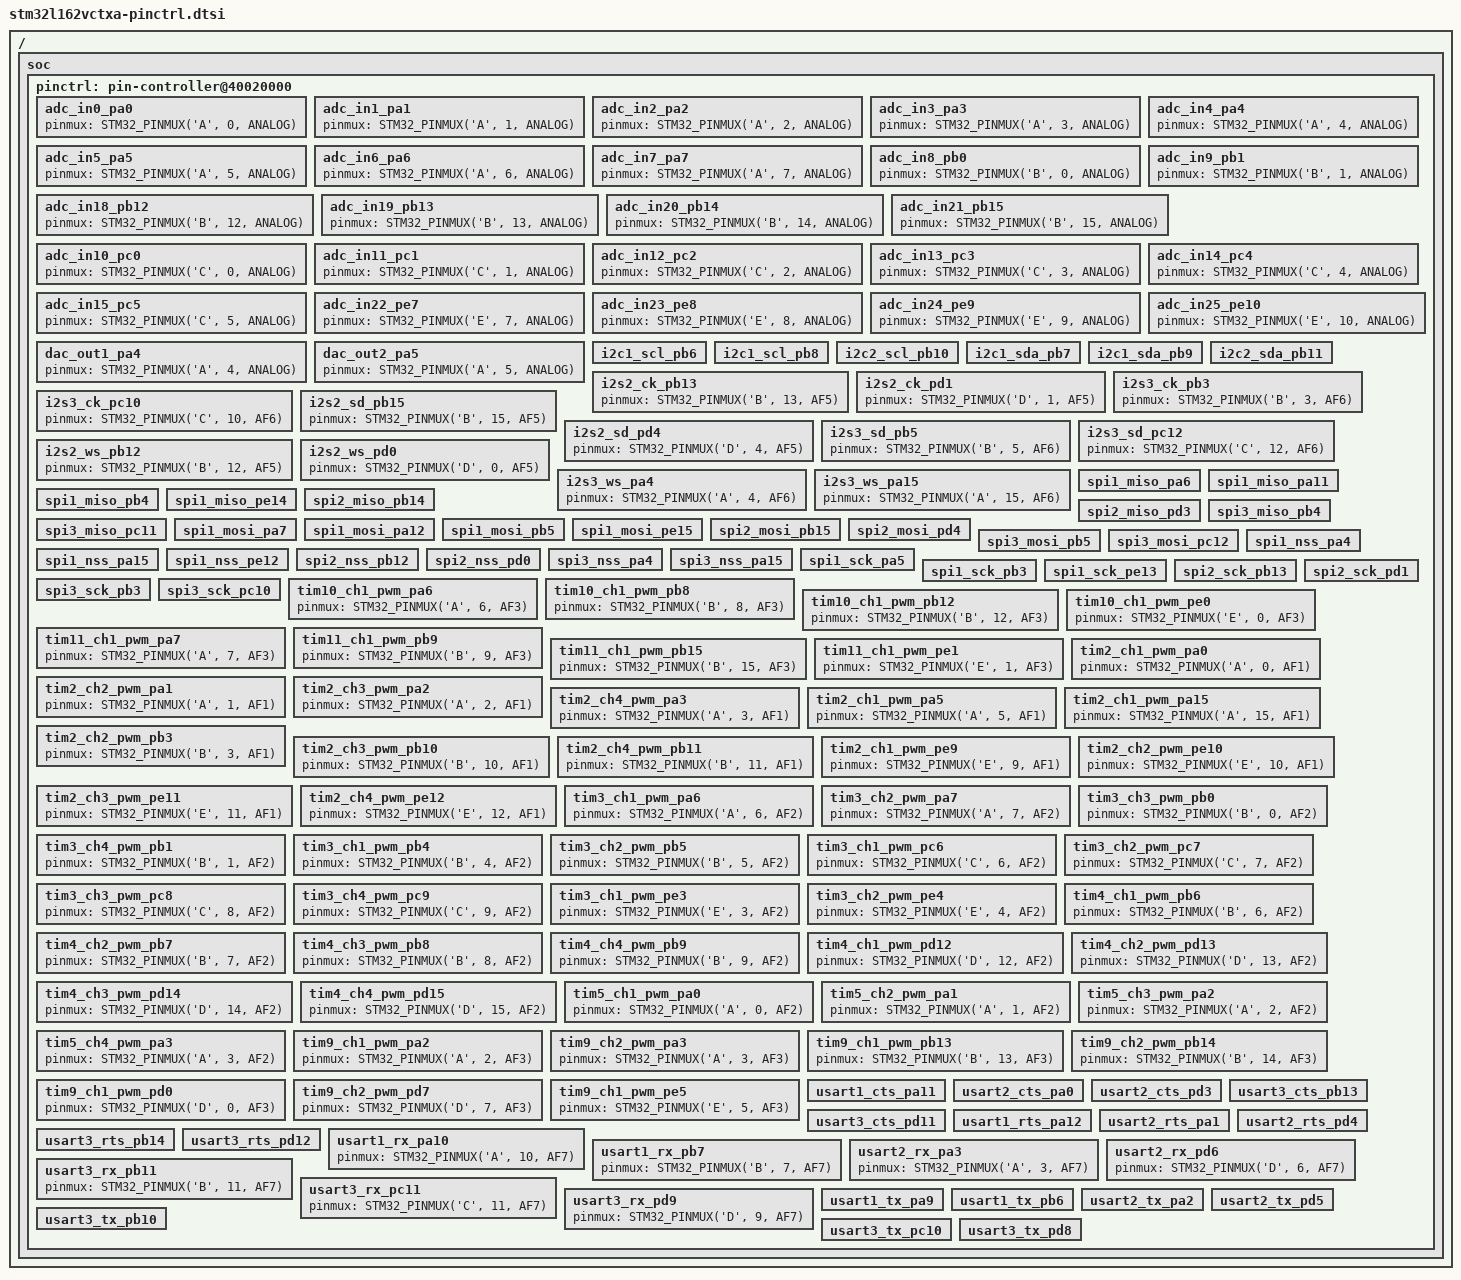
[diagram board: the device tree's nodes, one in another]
/*
 * NOTE: Autogenerated file using genpinctrl.py
 *
 * SPDX-License-Identifier: Apache-2.0
 */

#include <dt-bindings/pinctrl/stm32-pinctrl.h>

/ {
	soc {
		pinctrl: pin-controller@40020000 {

			/* ADC_IN / ADC_INN / ADC_INP */

			adc_in0_pa0: adc_in0_pa0 {
				pinmux = <STM32_PINMUX('A', 0, ANALOG)>;
			};

			adc_in1_pa1: adc_in1_pa1 {
				pinmux = <STM32_PINMUX('A', 1, ANALOG)>;
			};

			adc_in2_pa2: adc_in2_pa2 {
				pinmux = <STM32_PINMUX('A', 2, ANALOG)>;
			};

			adc_in3_pa3: adc_in3_pa3 {
				pinmux = <STM32_PINMUX('A', 3, ANALOG)>;
			};

			adc_in4_pa4: adc_in4_pa4 {
				pinmux = <STM32_PINMUX('A', 4, ANALOG)>;
			};

			adc_in5_pa5: adc_in5_pa5 {
				pinmux = <STM32_PINMUX('A', 5, ANALOG)>;
			};

			adc_in6_pa6: adc_in6_pa6 {
				pinmux = <STM32_PINMUX('A', 6, ANALOG)>;
			};

			adc_in7_pa7: adc_in7_pa7 {
				pinmux = <STM32_PINMUX('A', 7, ANALOG)>;
			};

			adc_in8_pb0: adc_in8_pb0 {
				pinmux = <STM32_PINMUX('B', 0, ANALOG)>;
			};

			adc_in9_pb1: adc_in9_pb1 {
				pinmux = <STM32_PINMUX('B', 1, ANALOG)>;
			};

			adc_in18_pb12: adc_in18_pb12 {
				pinmux = <STM32_PINMUX('B', 12, ANALOG)>;
			};

			adc_in19_pb13: adc_in19_pb13 {
				pinmux = <STM32_PINMUX('B', 13, ANALOG)>;
			};

			adc_in20_pb14: adc_in20_pb14 {
				pinmux = <STM32_PINMUX('B', 14, ANALOG)>;
			};

			adc_in21_pb15: adc_in21_pb15 {
				pinmux = <STM32_PINMUX('B', 15, ANALOG)>;
			};

			adc_in10_pc0: adc_in10_pc0 {
				pinmux = <STM32_PINMUX('C', 0, ANALOG)>;
			};

			adc_in11_pc1: adc_in11_pc1 {
				pinmux = <STM32_PINMUX('C', 1, ANALOG)>;
			};

			adc_in12_pc2: adc_in12_pc2 {
				pinmux = <STM32_PINMUX('C', 2, ANALOG)>;
			};

			adc_in13_pc3: adc_in13_pc3 {
				pinmux = <STM32_PINMUX('C', 3, ANALOG)>;
			};

			adc_in14_pc4: adc_in14_pc4 {
				pinmux = <STM32_PINMUX('C', 4, ANALOG)>;
			};

			adc_in15_pc5: adc_in15_pc5 {
				pinmux = <STM32_PINMUX('C', 5, ANALOG)>;
			};

			adc_in22_pe7: adc_in22_pe7 {
				pinmux = <STM32_PINMUX('E', 7, ANALOG)>;
			};

			adc_in23_pe8: adc_in23_pe8 {
				pinmux = <STM32_PINMUX('E', 8, ANALOG)>;
			};

			adc_in24_pe9: adc_in24_pe9 {
				pinmux = <STM32_PINMUX('E', 9, ANALOG)>;
			};

			adc_in25_pe10: adc_in25_pe10 {
				pinmux = <STM32_PINMUX('E', 10, ANALOG)>;
			};

			/* DAC_OUT */

			dac_out1_pa4: dac_out1_pa4 {
				pinmux = <STM32_PINMUX('A', 4, ANALOG)>;
			};

			dac_out2_pa5: dac_out2_pa5 {
				pinmux = <STM32_PINMUX('A', 5, ANALOG)>;
			};

			/* I2C_SCL */

			i2c1_scl_pb6: i2c1_scl_pb6 {
				pinmux = <STM32_PINMUX('B', 6, AF4)>;
				bias-pull-up;
				drive-open-drain;
			};

			i2c1_scl_pb8: i2c1_scl_pb8 {
				pinmux = <STM32_PINMUX('B', 8, AF4)>;
				bias-pull-up;
				drive-open-drain;
			};

			i2c2_scl_pb10: i2c2_scl_pb10 {
				pinmux = <STM32_PINMUX('B', 10, AF4)>;
				bias-pull-up;
				drive-open-drain;
			};

			/* I2C_SDA */

			i2c1_sda_pb7: i2c1_sda_pb7 {
				pinmux = <STM32_PINMUX('B', 7, AF4)>;
				bias-pull-up;
				drive-open-drain;
			};

			i2c1_sda_pb9: i2c1_sda_pb9 {
				pinmux = <STM32_PINMUX('B', 9, AF4)>;
				bias-pull-up;
				drive-open-drain;
			};

			i2c2_sda_pb11: i2c2_sda_pb11 {
				pinmux = <STM32_PINMUX('B', 11, AF4)>;
				bias-pull-up;
				drive-open-drain;
			};

			/* I2S_CK */

			i2s2_ck_pb13: i2s2_ck_pb13 {
				pinmux = <STM32_PINMUX('B', 13, AF5)>;
			};

			i2s2_ck_pd1: i2s2_ck_pd1 {
				pinmux = <STM32_PINMUX('D', 1, AF5)>;
			};

			i2s3_ck_pb3: i2s3_ck_pb3 {
				pinmux = <STM32_PINMUX('B', 3, AF6)>;
			};

			i2s3_ck_pc10: i2s3_ck_pc10 {
				pinmux = <STM32_PINMUX('C', 10, AF6)>;
			};

			/* I2S_SD */

			i2s2_sd_pb15: i2s2_sd_pb15 {
				pinmux = <STM32_PINMUX('B', 15, AF5)>;
			};

			i2s2_sd_pd4: i2s2_sd_pd4 {
				pinmux = <STM32_PINMUX('D', 4, AF5)>;
			};

			i2s3_sd_pb5: i2s3_sd_pb5 {
				pinmux = <STM32_PINMUX('B', 5, AF6)>;
			};

			i2s3_sd_pc12: i2s3_sd_pc12 {
				pinmux = <STM32_PINMUX('C', 12, AF6)>;
			};

			/* I2S_WS */

			i2s2_ws_pb12: i2s2_ws_pb12 {
				pinmux = <STM32_PINMUX('B', 12, AF5)>;
			};

			i2s2_ws_pd0: i2s2_ws_pd0 {
				pinmux = <STM32_PINMUX('D', 0, AF5)>;
			};

			i2s3_ws_pa4: i2s3_ws_pa4 {
				pinmux = <STM32_PINMUX('A', 4, AF6)>;
			};

			i2s3_ws_pa15: i2s3_ws_pa15 {
				pinmux = <STM32_PINMUX('A', 15, AF6)>;
			};

			/* SPI_MISO */

			spi1_miso_pa6: spi1_miso_pa6 {
				pinmux = <STM32_PINMUX('A', 6, AF5)>;
				bias-pull-down;
			};

			spi1_miso_pa11: spi1_miso_pa11 {
				pinmux = <STM32_PINMUX('A', 11, AF5)>;
				bias-pull-down;
			};

			spi1_miso_pb4: spi1_miso_pb4 {
				pinmux = <STM32_PINMUX('B', 4, AF5)>;
				bias-pull-down;
			};

			spi1_miso_pe14: spi1_miso_pe14 {
				pinmux = <STM32_PINMUX('E', 14, AF5)>;
				bias-pull-down;
			};

			spi2_miso_pb14: spi2_miso_pb14 {
				pinmux = <STM32_PINMUX('B', 14, AF5)>;
				bias-pull-down;
			};

			spi2_miso_pd3: spi2_miso_pd3 {
				pinmux = <STM32_PINMUX('D', 3, AF5)>;
				bias-pull-down;
			};

			spi3_miso_pb4: spi3_miso_pb4 {
				pinmux = <STM32_PINMUX('B', 4, AF6)>;
				bias-pull-down;
			};

			spi3_miso_pc11: spi3_miso_pc11 {
				pinmux = <STM32_PINMUX('C', 11, AF6)>;
				bias-pull-down;
			};

			/* SPI_MOSI */

			spi1_mosi_pa7: spi1_mosi_pa7 {
				pinmux = <STM32_PINMUX('A', 7, AF5)>;
				bias-pull-down;
			};

			spi1_mosi_pa12: spi1_mosi_pa12 {
				pinmux = <STM32_PINMUX('A', 12, AF5)>;
				bias-pull-down;
			};

			spi1_mosi_pb5: spi1_mosi_pb5 {
				pinmux = <STM32_PINMUX('B', 5, AF5)>;
				bias-pull-down;
			};

			spi1_mosi_pe15: spi1_mosi_pe15 {
				pinmux = <STM32_PINMUX('E', 15, AF5)>;
				bias-pull-down;
			};

			spi2_mosi_pb15: spi2_mosi_pb15 {
				pinmux = <STM32_PINMUX('B', 15, AF5)>;
				bias-pull-down;
			};

			spi2_mosi_pd4: spi2_mosi_pd4 {
				pinmux = <STM32_PINMUX('D', 4, AF5)>;
				bias-pull-down;
			};

			spi3_mosi_pb5: spi3_mosi_pb5 {
				pinmux = <STM32_PINMUX('B', 5, AF6)>;
				bias-pull-down;
			};

			spi3_mosi_pc12: spi3_mosi_pc12 {
				pinmux = <STM32_PINMUX('C', 12, AF6)>;
				bias-pull-down;
			};

			/* SPI_NSS */

			spi1_nss_pa4: spi1_nss_pa4 {
				pinmux = <STM32_PINMUX('A', 4, AF5)>;
				bias-pull-up;
			};

			spi1_nss_pa15: spi1_nss_pa15 {
				pinmux = <STM32_PINMUX('A', 15, AF5)>;
				bias-pull-up;
			};

			spi1_nss_pe12: spi1_nss_pe12 {
				pinmux = <STM32_PINMUX('E', 12, AF5)>;
				bias-pull-up;
			};

			spi2_nss_pb12: spi2_nss_pb12 {
				pinmux = <STM32_PINMUX('B', 12, AF5)>;
				bias-pull-up;
			};

			spi2_nss_pd0: spi2_nss_pd0 {
				pinmux = <STM32_PINMUX('D', 0, AF5)>;
				bias-pull-up;
			};

			spi3_nss_pa4: spi3_nss_pa4 {
				pinmux = <STM32_PINMUX('A', 4, AF6)>;
				bias-pull-up;
			};

			spi3_nss_pa15: spi3_nss_pa15 {
				pinmux = <STM32_PINMUX('A', 15, AF6)>;
				bias-pull-up;
			};

			/* SPI_SCK */

			spi1_sck_pa5: spi1_sck_pa5 {
				pinmux = <STM32_PINMUX('A', 5, AF5)>;
				slew-rate = "very-high-speed";
			};

			spi1_sck_pb3: spi1_sck_pb3 {
				pinmux = <STM32_PINMUX('B', 3, AF5)>;
				slew-rate = "very-high-speed";
			};

			spi1_sck_pe13: spi1_sck_pe13 {
				pinmux = <STM32_PINMUX('E', 13, AF5)>;
				slew-rate = "very-high-speed";
			};

			spi2_sck_pb13: spi2_sck_pb13 {
				pinmux = <STM32_PINMUX('B', 13, AF5)>;
				slew-rate = "very-high-speed";
			};

			spi2_sck_pd1: spi2_sck_pd1 {
				pinmux = <STM32_PINMUX('D', 1, AF5)>;
				slew-rate = "very-high-speed";
			};

			spi3_sck_pb3: spi3_sck_pb3 {
				pinmux = <STM32_PINMUX('B', 3, AF6)>;
				slew-rate = "very-high-speed";
			};

			spi3_sck_pc10: spi3_sck_pc10 {
				pinmux = <STM32_PINMUX('C', 10, AF6)>;
				slew-rate = "very-high-speed";
			};

			/* TIM_CH_PWM / TIM_CHN_PWM */

			tim10_ch1_pwm_pa6: tim10_ch1_pwm_pa6 {
				pinmux = <STM32_PINMUX('A', 6, AF3)>;
			};

			tim10_ch1_pwm_pb8: tim10_ch1_pwm_pb8 {
				pinmux = <STM32_PINMUX('B', 8, AF3)>;
			};

			tim10_ch1_pwm_pb12: tim10_ch1_pwm_pb12 {
				pinmux = <STM32_PINMUX('B', 12, AF3)>;
			};

			tim10_ch1_pwm_pe0: tim10_ch1_pwm_pe0 {
				pinmux = <STM32_PINMUX('E', 0, AF3)>;
			};

			tim11_ch1_pwm_pa7: tim11_ch1_pwm_pa7 {
				pinmux = <STM32_PINMUX('A', 7, AF3)>;
			};

			tim11_ch1_pwm_pb9: tim11_ch1_pwm_pb9 {
				pinmux = <STM32_PINMUX('B', 9, AF3)>;
			};

			tim11_ch1_pwm_pb15: tim11_ch1_pwm_pb15 {
				pinmux = <STM32_PINMUX('B', 15, AF3)>;
			};

			tim11_ch1_pwm_pe1: tim11_ch1_pwm_pe1 {
				pinmux = <STM32_PINMUX('E', 1, AF3)>;
			};

			tim2_ch1_pwm_pa0: tim2_ch1_pwm_pa0 {
				pinmux = <STM32_PINMUX('A', 0, AF1)>;
			};

			tim2_ch2_pwm_pa1: tim2_ch2_pwm_pa1 {
				pinmux = <STM32_PINMUX('A', 1, AF1)>;
			};

			tim2_ch3_pwm_pa2: tim2_ch3_pwm_pa2 {
				pinmux = <STM32_PINMUX('A', 2, AF1)>;
			};

			tim2_ch4_pwm_pa3: tim2_ch4_pwm_pa3 {
				pinmux = <STM32_PINMUX('A', 3, AF1)>;
			};

			tim2_ch1_pwm_pa5: tim2_ch1_pwm_pa5 {
				pinmux = <STM32_PINMUX('A', 5, AF1)>;
			};

			tim2_ch1_pwm_pa15: tim2_ch1_pwm_pa15 {
				pinmux = <STM32_PINMUX('A', 15, AF1)>;
			};

			tim2_ch2_pwm_pb3: tim2_ch2_pwm_pb3 {
				pinmux = <STM32_PINMUX('B', 3, AF1)>;
			};

			tim2_ch3_pwm_pb10: tim2_ch3_pwm_pb10 {
				pinmux = <STM32_PINMUX('B', 10, AF1)>;
			};

			tim2_ch4_pwm_pb11: tim2_ch4_pwm_pb11 {
				pinmux = <STM32_PINMUX('B', 11, AF1)>;
			};

			tim2_ch1_pwm_pe9: tim2_ch1_pwm_pe9 {
				pinmux = <STM32_PINMUX('E', 9, AF1)>;
			};

			tim2_ch2_pwm_pe10: tim2_ch2_pwm_pe10 {
				pinmux = <STM32_PINMUX('E', 10, AF1)>;
			};

			tim2_ch3_pwm_pe11: tim2_ch3_pwm_pe11 {
				pinmux = <STM32_PINMUX('E', 11, AF1)>;
			};

			tim2_ch4_pwm_pe12: tim2_ch4_pwm_pe12 {
				pinmux = <STM32_PINMUX('E', 12, AF1)>;
			};

			tim3_ch1_pwm_pa6: tim3_ch1_pwm_pa6 {
				pinmux = <STM32_PINMUX('A', 6, AF2)>;
			};

			tim3_ch2_pwm_pa7: tim3_ch2_pwm_pa7 {
				pinmux = <STM32_PINMUX('A', 7, AF2)>;
			};

			tim3_ch3_pwm_pb0: tim3_ch3_pwm_pb0 {
				pinmux = <STM32_PINMUX('B', 0, AF2)>;
			};

			tim3_ch4_pwm_pb1: tim3_ch4_pwm_pb1 {
				pinmux = <STM32_PINMUX('B', 1, AF2)>;
			};

			tim3_ch1_pwm_pb4: tim3_ch1_pwm_pb4 {
				pinmux = <STM32_PINMUX('B', 4, AF2)>;
			};

			tim3_ch2_pwm_pb5: tim3_ch2_pwm_pb5 {
				pinmux = <STM32_PINMUX('B', 5, AF2)>;
			};

			tim3_ch1_pwm_pc6: tim3_ch1_pwm_pc6 {
				pinmux = <STM32_PINMUX('C', 6, AF2)>;
			};

			tim3_ch2_pwm_pc7: tim3_ch2_pwm_pc7 {
				pinmux = <STM32_PINMUX('C', 7, AF2)>;
			};

			tim3_ch3_pwm_pc8: tim3_ch3_pwm_pc8 {
				pinmux = <STM32_PINMUX('C', 8, AF2)>;
			};

			tim3_ch4_pwm_pc9: tim3_ch4_pwm_pc9 {
				pinmux = <STM32_PINMUX('C', 9, AF2)>;
			};

			tim3_ch1_pwm_pe3: tim3_ch1_pwm_pe3 {
				pinmux = <STM32_PINMUX('E', 3, AF2)>;
			};

			tim3_ch2_pwm_pe4: tim3_ch2_pwm_pe4 {
				pinmux = <STM32_PINMUX('E', 4, AF2)>;
			};

			tim4_ch1_pwm_pb6: tim4_ch1_pwm_pb6 {
				pinmux = <STM32_PINMUX('B', 6, AF2)>;
			};

			tim4_ch2_pwm_pb7: tim4_ch2_pwm_pb7 {
				pinmux = <STM32_PINMUX('B', 7, AF2)>;
			};

			tim4_ch3_pwm_pb8: tim4_ch3_pwm_pb8 {
				pinmux = <STM32_PINMUX('B', 8, AF2)>;
			};

			tim4_ch4_pwm_pb9: tim4_ch4_pwm_pb9 {
				pinmux = <STM32_PINMUX('B', 9, AF2)>;
			};

			tim4_ch1_pwm_pd12: tim4_ch1_pwm_pd12 {
				pinmux = <STM32_PINMUX('D', 12, AF2)>;
			};

			tim4_ch2_pwm_pd13: tim4_ch2_pwm_pd13 {
				pinmux = <STM32_PINMUX('D', 13, AF2)>;
			};

			tim4_ch3_pwm_pd14: tim4_ch3_pwm_pd14 {
				pinmux = <STM32_PINMUX('D', 14, AF2)>;
			};

			tim4_ch4_pwm_pd15: tim4_ch4_pwm_pd15 {
				pinmux = <STM32_PINMUX('D', 15, AF2)>;
			};

			tim5_ch1_pwm_pa0: tim5_ch1_pwm_pa0 {
				pinmux = <STM32_PINMUX('A', 0, AF2)>;
			};

			tim5_ch2_pwm_pa1: tim5_ch2_pwm_pa1 {
				pinmux = <STM32_PINMUX('A', 1, AF2)>;
			};

			tim5_ch3_pwm_pa2: tim5_ch3_pwm_pa2 {
				pinmux = <STM32_PINMUX('A', 2, AF2)>;
			};

			tim5_ch4_pwm_pa3: tim5_ch4_pwm_pa3 {
				pinmux = <STM32_PINMUX('A', 3, AF2)>;
			};

			tim9_ch1_pwm_pa2: tim9_ch1_pwm_pa2 {
				pinmux = <STM32_PINMUX('A', 2, AF3)>;
			};

			tim9_ch2_pwm_pa3: tim9_ch2_pwm_pa3 {
				pinmux = <STM32_PINMUX('A', 3, AF3)>;
			};

			tim9_ch1_pwm_pb13: tim9_ch1_pwm_pb13 {
				pinmux = <STM32_PINMUX('B', 13, AF3)>;
			};

			tim9_ch2_pwm_pb14: tim9_ch2_pwm_pb14 {
				pinmux = <STM32_PINMUX('B', 14, AF3)>;
			};

			tim9_ch1_pwm_pd0: tim9_ch1_pwm_pd0 {
				pinmux = <STM32_PINMUX('D', 0, AF3)>;
			};

			tim9_ch2_pwm_pd7: tim9_ch2_pwm_pd7 {
				pinmux = <STM32_PINMUX('D', 7, AF3)>;
			};

			tim9_ch1_pwm_pe5: tim9_ch1_pwm_pe5 {
				pinmux = <STM32_PINMUX('E', 5, AF3)>;
			};

			/* UART_CTS / USART_CTS / LPUART_CTS */

			usart1_cts_pa11: usart1_cts_pa11 {
				pinmux = <STM32_PINMUX('A', 11, AF7)>;
				bias-pull-up;
				drive-open-drain;
			};

			usart2_cts_pa0: usart2_cts_pa0 {
				pinmux = <STM32_PINMUX('A', 0, AF7)>;
				bias-pull-up;
				drive-open-drain;
			};

			usart2_cts_pd3: usart2_cts_pd3 {
				pinmux = <STM32_PINMUX('D', 3, AF7)>;
				bias-pull-up;
				drive-open-drain;
			};

			usart3_cts_pb13: usart3_cts_pb13 {
				pinmux = <STM32_PINMUX('B', 13, AF7)>;
				bias-pull-up;
				drive-open-drain;
			};

			usart3_cts_pd11: usart3_cts_pd11 {
				pinmux = <STM32_PINMUX('D', 11, AF7)>;
				bias-pull-up;
				drive-open-drain;
			};

			/* UART_RTS / USART_RTS / LPUART_RTS */

			usart1_rts_pa12: usart1_rts_pa12 {
				pinmux = <STM32_PINMUX('A', 12, AF7)>;
				bias-pull-up;
				drive-open-drain;
			};

			usart2_rts_pa1: usart2_rts_pa1 {
				pinmux = <STM32_PINMUX('A', 1, AF7)>;
				bias-pull-up;
				drive-open-drain;
			};

			usart2_rts_pd4: usart2_rts_pd4 {
				pinmux = <STM32_PINMUX('D', 4, AF7)>;
				bias-pull-up;
				drive-open-drain;
			};

			usart3_rts_pb14: usart3_rts_pb14 {
				pinmux = <STM32_PINMUX('B', 14, AF7)>;
				bias-pull-up;
				drive-open-drain;
			};

			usart3_rts_pd12: usart3_rts_pd12 {
				pinmux = <STM32_PINMUX('D', 12, AF7)>;
				bias-pull-up;
				drive-open-drain;
			};

			/* UART_RX / USART_RX / LPUART_RX */

			usart1_rx_pa10: usart1_rx_pa10 {
				pinmux = <STM32_PINMUX('A', 10, AF7)>;
			};

			usart1_rx_pb7: usart1_rx_pb7 {
				pinmux = <STM32_PINMUX('B', 7, AF7)>;
			};

			usart2_rx_pa3: usart2_rx_pa3 {
				pinmux = <STM32_PINMUX('A', 3, AF7)>;
			};

			usart2_rx_pd6: usart2_rx_pd6 {
				pinmux = <STM32_PINMUX('D', 6, AF7)>;
			};

			usart3_rx_pb11: usart3_rx_pb11 {
				pinmux = <STM32_PINMUX('B', 11, AF7)>;
			};

			usart3_rx_pc11: usart3_rx_pc11 {
				pinmux = <STM32_PINMUX('C', 11, AF7)>;
			};

			usart3_rx_pd9: usart3_rx_pd9 {
				pinmux = <STM32_PINMUX('D', 9, AF7)>;
			};

			/* UART_TX / USART_TX / LPUART_TX */

			usart1_tx_pa9: usart1_tx_pa9 {
				pinmux = <STM32_PINMUX('A', 9, AF7)>;
				bias-pull-up;
			};

			usart1_tx_pb6: usart1_tx_pb6 {
				pinmux = <STM32_PINMUX('B', 6, AF7)>;
				bias-pull-up;
			};

			usart2_tx_pa2: usart2_tx_pa2 {
				pinmux = <STM32_PINMUX('A', 2, AF7)>;
				bias-pull-up;
			};

			usart2_tx_pd5: usart2_tx_pd5 {
				pinmux = <STM32_PINMUX('D', 5, AF7)>;
				bias-pull-up;
			};

			usart3_tx_pb10: usart3_tx_pb10 {
				pinmux = <STM32_PINMUX('B', 10, AF7)>;
				bias-pull-up;
			};

			usart3_tx_pc10: usart3_tx_pc10 {
				pinmux = <STM32_PINMUX('C', 10, AF7)>;
				bias-pull-up;
			};

			usart3_tx_pd8: usart3_tx_pd8 {
				pinmux = <STM32_PINMUX('D', 8, AF7)>;
				bias-pull-up;
			};

		};
	};
};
